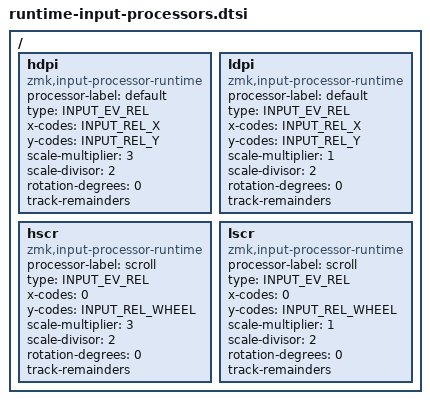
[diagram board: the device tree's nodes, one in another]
/*
* Copyright (c) 2026 The ZMK Contributors
* SPDX-License-Identifier: MIT
*
* Common Runtime Input Processor Configurations
*
* This file provides pre-configured runtime input processors that can be easily
* included and used in keyboard configurations. Users can override these or
* create their own custom processors.
*/

/ {
	// High DPI
	/omit-if-no-ref/
	hdpi: hdpi {
		compatible = "zmk,input-processor-runtime";
		processor-label = "default";
		type = <INPUT_EV_REL>;
		x-codes = <INPUT_REL_X>;
		y-codes = <INPUT_REL_Y>;
		// x1.5 scaling
		scale-multiplier = <3>;
		scale-divisor = <2>;
		rotation-degrees = <0>;
		track-remainders;
		
		#binding-cells = <0>;
	};
	
	// Low DPI
	/omit-if-no-ref/
	ldpi: ldpi {
		compatible = "zmk,input-processor-runtime";
		processor-label = "default";
		type = <INPUT_EV_REL>;
		x-codes = <INPUT_REL_X>;
		y-codes = <INPUT_REL_Y>;
		// x0.5 scaling
		scale-multiplier = <1>;
		scale-divisor = <2>;
		rotation-degrees = <0>;
		track-remainders;
		
		#binding-cells = <0>;
	};
	
	// High Speed Scroll
	/omit-if-no-ref/
	hscr: hscr {
		compatible = "zmk,input-processor-runtime";
		processor-label = "scroll";
		type = <INPUT_EV_REL>;
		x-codes = <0>;// Unused, but must match y-codes length
		y-codes = <INPUT_REL_WHEEL>;
		scale-multiplier = <3>;
		scale-divisor = <2>;
		rotation-degrees = <0>;
		track-remainders;
		
		#binding-cells = <0>;
	};
	
	// Low Speed Scroll
	/omit-if-no-ref/
	lscr: lscr {
		compatible = "zmk,input-processor-runtime";
		processor-label = "scroll";
		type = <INPUT_EV_REL>;
		x-codes = <0>;// Unused, but must match y-codes length
		y-codes = <INPUT_REL_WHEEL>;
		scale-multiplier = <1>;
		scale-divisor = <2>;
		rotation-degrees = <0>;
		track-remainders;
		
		#binding-cells = <0>;
	};
};
